# ATmega406 device description
Architecture: AVR8; Family: megaAVR
Registers are 8-bit, access not given, no defined reset value unless marked. A register's access mark holds for its fields unless they carry their own. Offsets are from the block's base; [hi:lo] are bit positions; {n}, {i} and the like mark numbered series.

## FET — FET Control
Instances: FET 0x00
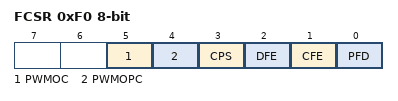
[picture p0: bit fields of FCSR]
0xF0 FCSR
  [5] PWMOC — Pulse Width Modulation of OC output
  [4] PWMOPC — Pulse Width Modulation Modulation of OPC output
  [3] CPS — Current Protection Status
  [2] DFE — Discharge FET Enable
  [1] CFE — Charge FET Enable
  [0] PFD — Precharge FET disable

## COULOMB_COUNTER
Instances: COULOMB_COUNTER 0x00
{0xE0+i} CADAC{i} (i=0..3) — ADC Accumulate Current
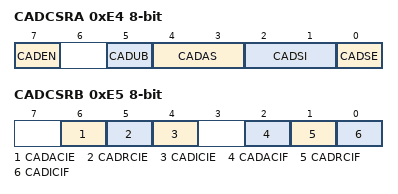
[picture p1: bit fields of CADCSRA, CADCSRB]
0xE4 CADCSRA — CC-ADC Control and Status Register A
  [7] CADEN — When the CADEN bit is cleared (zero), the CC-ADC is disabled. When the CADEN bit is set (one), the CC-ADC will continuously measure the voltage drop over the external sense resistor RSENSE. In Power-down, only the Regular Current detection is active. In Power-off, the CC-ADC is always disabled.
  [5] CADUB — CC_ADC Update Busy
  [4:3] CADAS — CC_ADC Accumulate Current Select Bits
    0=125ms; 1=250ms; 2=500ms; 3=1000ms
  [2:1] CADSI — The CADSI bits determine the current sampling interval for the Regular Current detection in Power-down mode. The actual settings remain to be determined.
    0=125ms; 1=250ms; 2=500ms; 3=1000ms
  [0] CADSE — When the CADSE bit is written to one, the ongoing CC-ADC conversion is aborted, and the CC-ADC enters Regular Current detection mode.
0xE5 CADCSRB — CC-ADC Control and Status Register B
  [6] CADACIE
  [5] CADRCIE — Regular Current Interrupt Enable
  [4] CADICIE — CAD Instantenous Current Interrupt Enable
  [2] CADACIF — CC-ADC Accumulate Current Interrupt Flag
  [1] CADRCIF — CC-ADC Accumulate Current Interrupt Flag
  [0] CADICIF — CC-ADC Instantaneous Current Interrupt Flag
0xE6 CADRCC — CC-ADC Regular Charge Current
0xE7 CADRDC — CC-ADC Regular Discharge Current
0xE8 CADIC 16-bit — CC-ADC Instantaneous Current

## CELL_BALANCING
Instances: CELL_BALANCING 0x00
0xF1 CBCR — Cell Balancing Control Register
  [3:0] CBE (bit 1 of the value upward) — Cell Balancing Enables

## CPU — CPU Registers
Instances: CPU 0x00
Parameters: CORE_VERSION=V2E
0x3E GPIOR0 — General Purpose IO Register 0
0x4A GPIOR1 — General Purpose IO Register 1
0x4B GPIOR2 — General Purpose IO Register 2
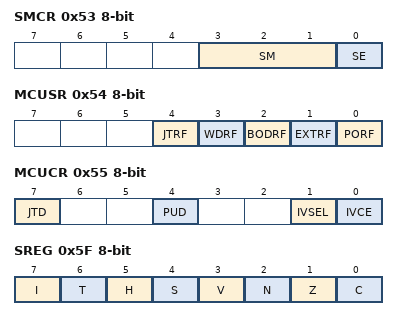
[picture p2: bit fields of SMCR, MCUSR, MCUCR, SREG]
0x53 SMCR — Sleep Mode Control Register
  [3:1] SM — Sleep Mode Select bits
    0=IDLE; 1=ADC (ADC Noise Reduction (If Available)); 2=PDOWN (Power Down); 3=PSAVE (Power Save); 4=POFF (Power Off)
  [0] SE — Sleep Enable
0x54 MCUSR — MCU Status Register
  [4] JTRF — JTAG Reset Flag
  [3] WDRF — Watchdog Reset Flag
  [2] BODRF — Brown-out Reset Flag
  [1] EXTRF — External Reset Flag
  [0] PORF — Power-on reset flag
0x55 MCUCR — MCU Control Register
  [7] JTD — JTAG Disable
  [4] PUD — Pull-up disable
  [1] IVSEL — Interrupt Vector Select
  [0] IVCE — Interrupt Vector Change Enable
0x5D SP 16-bit — Stack Pointer
0x5F SREG — Status Register
  [7] I — Global Interrupt Enable
  [6] T — Bit Copy Storage
  [5] H — Half Carry Flag
  [4] S — Sign Bit
  [3] V — Two's Complement Overflow Flag
  [2] N — Negative Flag
  [1] Z — Zero Flag
  [0] C — Carry Flag
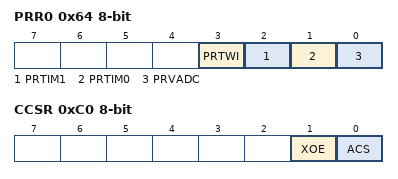
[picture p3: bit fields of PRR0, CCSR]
0x64 PRR0 — Power Reduction Register 0
  [3] PRTWI — Power Reduction TWI
  [2] PRTIM1 — Power Reduction Timer/Counter1
  [1] PRTIM0 — Power Reduction Timer/Counter0
  [0] PRVADC — Power Reduction V-ADC
0x66 FOSCCAL — Fast Oscillator Calibration Value
0x7E DIDR0 bits used 3:0 — Digital Input Disable Register
0xC0 CCSR — Clock Control and Status Register
  [1] XOE — 32 kHz Crystal Oscillator Enable
  [0] ACS — Asynchronous Clock Select

## WDT — Watchdog Timer
Instances: WDT 0x00
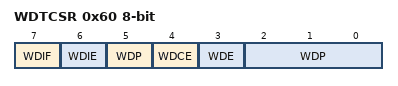
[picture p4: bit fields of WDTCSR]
0x60 WDTCSR — Watchdog Timer Control Register
  [7] WDIF — Watchdog Timeout Interrupt Flag
  [6] WDIE — Watchdog Timeout Interrupt Enable
  [4] WDCE — Watchdog Change Enable
  [3] WDE — Watch Dog Enable
  [5,2:0] WDP — Watchdog Timer Prescaler Bits
    0=Oscillator Cycles 2K; 1=Oscillator Cycles 4K; 2=Oscillator Cycles 8K; 3=Oscillator Cycles 16K; 4=Oscillator Cycles 32K; 5=Oscillator Cycles 64K; 6=Oscillator Cycles 128K; 7=Oscillator Cycles 256K; 8=Oscillator Cycles 512K; 9=Oscillator Cycles 1024K
